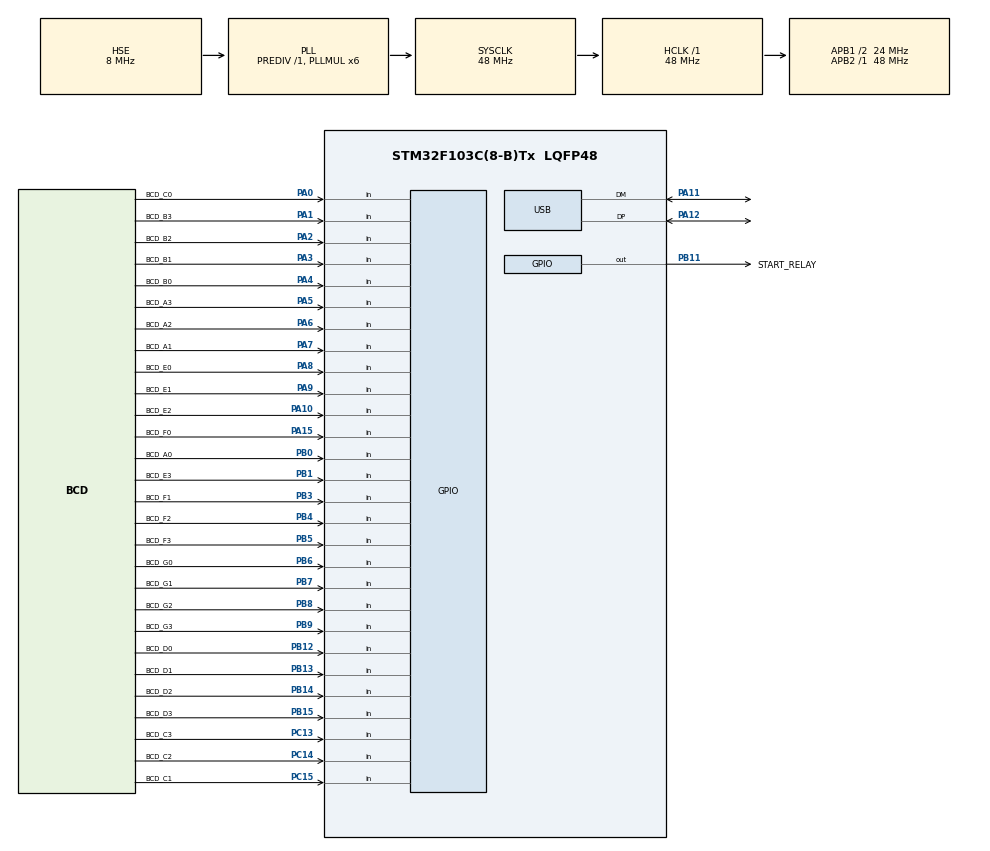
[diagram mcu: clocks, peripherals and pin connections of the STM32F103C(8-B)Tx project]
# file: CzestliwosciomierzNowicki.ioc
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Mcu.Family=STM32F1
Mcu.Name=STM32F103C(8-B)Tx
Mcu.Package=LQFP48
NVIC.PriorityGroup=NVIC_PRIORITYGROUP_4
NVIC.TIM1_UP_IRQn=true\:0\:0\:false\:false\:true\:true\:true
NVIC.USB_LP_CAN1_RX0_IRQn=true\:0\:0\:false\:false\:true\:false\:true
PA0-WKUP.GPIO_Label=BCD_C0
PA0-WKUP.Signal=GPIO_Input
PA1.GPIO_Label=BCD_B3
PA1.Signal=GPIO_Input
PA10.GPIO_Label=BCD_E2
PA10.Signal=GPIO_Input
PA11.Mode=Device
PA11.Signal=USB_DM
PA12.Mode=Device
PA12.Signal=USB_DP
PA13.Mode=Serial_Wire
PA13.Signal=SYS_JTMS-SWDIO
PA14.Mode=Serial_Wire
PA14.Signal=SYS_JTCK-SWCLK
PA15.GPIO_Label=BCD_F0
PA15.Signal=GPIO_Input
PA2.GPIO_Label=BCD_B2
PA2.Signal=GPIO_Input
PA3.GPIO_Label=BCD_B1
PA3.Signal=GPIO_Input
PA4.GPIO_Label=BCD_B0
PA4.Signal=GPIO_Input
PA5.GPIO_Label=BCD_A3
PA5.Signal=GPIO_Input
PA6.GPIO_Label=BCD_A2
PA6.Signal=GPIO_Input
PA7.GPIO_Label=BCD_A1
PA7.Signal=GPIO_Input
PA8.GPIO_Label=BCD_E0
PA8.Signal=GPIO_Input
PA9.GPIO_Label=BCD_E1
PA9.Signal=GPIO_Input
PB0.GPIO_Label=BCD_A0
PB0.Signal=GPIO_Input
PB1.GPIO_Label=BCD_E3
PB1.Signal=GPIO_Input
PB11.GPIO_Label=START_RELAY
PB11.Signal=GPIO_Output
PB12.GPIO_Label=BCD_D0
PB12.Signal=GPIO_Input
PB13.GPIO_Label=BCD_D1
PB13.Signal=GPIO_Input
PB14.GPIO_Label=BCD_D2
PB14.Signal=GPIO_Input
PB15.GPIO_Label=BCD_D3
PB15.Signal=GPIO_Input
PB3.GPIO_Label=BCD_F1
PB3.Signal=GPIO_Input
PB4.GPIO_Label=BCD_F2
PB4.Signal=GPIO_Input
PB5.GPIO_Label=BCD_F3
PB5.Signal=GPIO_Input
PB6.GPIO_Label=BCD_G0
PB6.Signal=GPIO_Input
PB7.GPIO_Label=BCD_G1
PB7.Signal=GPIO_Input
PB8.GPIO_Label=BCD_G2
PB8.Signal=GPIO_Input
PB9.GPIO_Label=BCD_G3
PB9.Signal=GPIO_Input
PC13-TAMPER-RTC.GPIO_Label=BCD_C3
PC13-TAMPER-RTC.Signal=GPIO_Input
PC14-OSC32_IN.GPIO_Label=BCD_C2
PC14-OSC32_IN.Signal=GPIO_Input
PC15-OSC32_OUT.GPIO_Label=BCD_C1
PC15-OSC32_OUT.Signal=GPIO_Input
PD0-OSC_IN.Mode=HSE-External-Oscillator
PD0-OSC_IN.Signal=RCC_OSC_IN
PD1-OSC_OUT.Mode=HSE-External-Oscillator
PD1-OSC_OUT.Signal=RCC_OSC_OUT
ProjectManager.HeapSize=0x200
ProjectManager.StackSize=0x400
ProjectManager.TargetToolchain=STM32CubeIDE
RCC.AHBFreq_Value=48000000
RCC.APB1CLKDivider=RCC_HCLK_DIV2
RCC.APB1Freq_Value=24000000
RCC.APB1TimFreq_Value=48000000
RCC.APB2Freq_Value=48000000
RCC.APB2TimFreq_Value=48000000
RCC.HCLKFreq_Value=48000000
RCC.PLLMUL=RCC_PLL_MUL6
RCC.PLLSourceVirtual=RCC_PLLSOURCE_HSE
RCC.SYSCLKFreq_VALUE=48000000
RCC.SYSCLKSource=RCC_SYSCLKSOURCE_PLLCLK
RCC.USBFreq_Value=48000000
TIM1.AutoReloadPreload=TIM_AUTORELOAD_PRELOAD_ENABLE
TIM1.Period=9
TIM1.Prescaler=47999
USB_DEVICE.CLASS_NAME_FS=CDC
USB_DEVICE.VirtualMode=Cdc
USB_DEVICE.VirtualModeFS=Cdc_FS
VP_TIM1_VS_ClockSourceINT.Mode=Internal
VP_USB_DEVICE_VS_USB_DEVICE_CDC_FS.Mode=CDC_FS
board=custom

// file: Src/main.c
/* USER CODE BEGIN Header */
/**
  ******************************************************************************
  * @file           : main.c
  * @brief          : Main program body
  ******************************************************************************
  * @attention
  *
  * <h2><center>&copy; Copyright (c) 2019 STMicroelectronics.
  * All rights reserved.</center></h2>
  *
  * This software component is licensed by ST under BSD 3-Clause license,
  * the "License"; You may not use this file except in compliance with the
  * License. You may obtain a copy of the License at:
  *                        opensource.org/licenses/BSD-3-Clause
  *
  ******************************************************************************
  */
/* USER CODE END Header */

#include "main.h"
#include "usb_device.h"

TIM_HandleTypeDef htim1;

void SystemClock_Config(void);
static void MX_GPIO_Init(void);
static void MX_TIM1_Init(void);

int main(void)
{

  /* MCU Configuration--------------------------------------------------------*/

  /* Reset of all peripherals, Initializes the Flash interface and the Systick. */
  HAL_Init();

  /* Configure the system clock */
  SystemClock_Config();

  /* Initialize all configured peripherals */
  MX_GPIO_Init();
  MX_USB_DEVICE_Init();
  MX_TIM1_Init();
  /* USER CODE BEGIN 2 */
  ch3_32_Intit(&htim1);
  /* USER CODE END 2 */

  /* Infinite loop */
  /* USER CODE BEGIN WHILE */
  while (1)
  {
	  //temporary -> timer 2 (pulse mode)
	  if(clear == 1){
		HAL_GPIO_WritePin(START_RELAY_GPIO_Port, START_RELAY_Pin, GPIO_PIN_SET);
		HAL_Delay(ch3_32_pulse_time);
		HAL_GPIO_WritePin(START_RELAY_GPIO_Port, START_RELAY_Pin, GPIO_PIN_RESET);
		clear = 0;
	  }
    /* USER CODE END WHILE */

  }
}

void SystemClock_Config(void)
{
  RCC_OscInitTypeDef RCC_OscInitStruct = {0};
  RCC_ClkInitTypeDef RCC_ClkInitStruct = {0};
  RCC_PeriphCLKInitTypeDef PeriphClkInit = {0};

  /** Initializes the CPU, AHB and APB busses clocks
  */
  RCC_OscInitStruct.OscillatorType = RCC_OSCILLATORTYPE_HSE;
  RCC_OscInitStruct.HSEState = RCC_HSE_ON;
  RCC_OscInitStruct.HSEPredivValue = RCC_HSE_PREDIV_DIV1;
  RCC_OscInitStruct.HSIState = RCC_HSI_ON;
  RCC_OscInitStruct.PLL.PLLState = RCC_PLL_ON;
  RCC_OscInitStruct.PLL.PLLSource = RCC_PLLSOURCE_HSE;
  RCC_OscInitStruct.PLL.PLLMUL = RCC_PLL_MUL6;
  if (HAL_RCC_OscConfig(&RCC_OscInitStruct) != HAL_OK)
  {
    Error_Handler();
  }
  /** Initializes the CPU, AHB and APB busses clocks
  */
  RCC_ClkInitStruct.ClockType = RCC_CLOCKTYPE_HCLK|RCC_CLOCKTYPE_SYSCLK
                              |RCC_CLOCKTYPE_PCLK1|RCC_CLOCKTYPE_PCLK2;
  RCC_ClkInitStruct.SYSCLKSource = RCC_SYSCLKSOURCE_PLLCLK;
  RCC_ClkInitStruct.AHBCLKDivider = RCC_SYSCLK_DIV1;
  RCC_ClkInitStruct.APB1CLKDivider = RCC_HCLK_DIV2;
  RCC_ClkInitStruct.APB2CLKDivider = RCC_HCLK_DIV1;

  if (HAL_RCC_ClockConfig(&RCC_ClkInitStruct, FLASH_LATENCY_1) != HAL_OK)
  {
    Error_Handler();
  }
  PeriphClkInit.PeriphClockSelection = RCC_PERIPHCLK_USB;
  PeriphClkInit.UsbClockSelection = RCC_USBCLKSOURCE_PLL;
  if (HAL_RCCEx_PeriphCLKConfig(&PeriphClkInit) != HAL_OK)
  {
    Error_Handler();
  }
}

static void MX_TIM1_Init(void)
{

  TIM_ClockConfigTypeDef sClockSourceConfig = {0};
  TIM_MasterConfigTypeDef sMasterConfig = {0};

  htim1.Instance = TIM1;
  htim1.Init.Prescaler = 47999;
  htim1.Init.CounterMode = TIM_COUNTERMODE_UP;
  htim1.Init.Period = 9;
  htim1.Init.ClockDivision = TIM_CLOCKDIVISION_DIV1;
  htim1.Init.RepetitionCounter = 0;
  htim1.Init.AutoReloadPreload = TIM_AUTORELOAD_PRELOAD_ENABLE;
  if (HAL_TIM_Base_Init(&htim1) != HAL_OK)
  {
    Error_Handler();
  }
  sClockSourceConfig.ClockSource = TIM_CLOCKSOURCE_INTERNAL;
  if (HAL_TIM_ConfigClockSource(&htim1, &sClockSourceConfig) != HAL_OK)
  {
    Error_Handler();
  }
  sMasterConfig.MasterOutputTrigger = TIM_TRGO_RESET;
  sMasterConfig.MasterSlaveMode = TIM_MASTERSLAVEMODE_DISABLE;
  if (HAL_TIMEx_MasterConfigSynchronization(&htim1, &sMasterConfig) != HAL_OK)
  {
    Error_Handler();
  }

}

static void MX_GPIO_Init(void)
{
  GPIO_InitTypeDef GPIO_InitStruct = {0};

  /* GPIO Ports Clock Enable */
  __HAL_RCC_GPIOC_CLK_ENABLE();
  __HAL_RCC_GPIOD_CLK_ENABLE();
  __HAL_RCC_GPIOA_CLK_ENABLE();
  __HAL_RCC_GPIOB_CLK_ENABLE();

  /*Configure GPIO pin Output Level */
  HAL_GPIO_WritePin(START_RELAY_GPIO_Port, START_RELAY_Pin, GPIO_PIN_RESET);

  /*Configure GPIO pins : BCD_C3_Pin BCD_C2_Pin BCD_C1_Pin */
  GPIO_InitStruct.Pin = BCD_C3_Pin|BCD_C2_Pin|BCD_C1_Pin;
  GPIO_InitStruct.Mode = GPIO_MODE_INPUT;
  GPIO_InitStruct.Pull = GPIO_NOPULL;
  HAL_GPIO_Init(GPIOC, &GPIO_InitStruct);

  /*Configure GPIO pins : BCD_C0_Pin BCD_B3_Pin BCD_B2_Pin BCD_B1_Pin
                           BCD_B0_Pin BCD_A3_Pin BCD_A2_Pin BCD_A1_Pin
                           BCD_E0_Pin BCD_E1_Pin BCD_E2_Pin BCD_F0_Pin */
  GPIO_InitStruct.Pin = BCD_C0_Pin|BCD_B3_Pin|BCD_B2_Pin|BCD_B1_Pin
                          |BCD_B0_Pin|BCD_A3_Pin|BCD_A2_Pin|BCD_A1_Pin
                          |BCD_E0_Pin|BCD_E1_Pin|BCD_E2_Pin|BCD_F0_Pin;
  GPIO_InitStruct.Mode = GPIO_MODE_INPUT;
  GPIO_InitStruct.Pull = GPIO_NOPULL;
  HAL_GPIO_Init(GPIOA, &GPIO_InitStruct);

  /*Configure GPIO pins : BCD_A0_Pin BCD_E3_Pin BCD_D0_Pin BCD_D1_Pin
                           BCD_D2_Pin BCD_D3_Pin BCD_F1_Pin BCD_F2_Pin
                           BCD_F3_Pin BCD_G0_Pin BCD_G1_Pin BCD_G2_Pin
                           BCD_G3_Pin */
  GPIO_InitStruct.Pin = BCD_A0_Pin|BCD_E3_Pin|BCD_D0_Pin|BCD_D1_Pin
                          |BCD_D2_Pin|BCD_D3_Pin|BCD_F1_Pin|BCD_F2_Pin
                          |BCD_F3_Pin|BCD_G0_Pin|BCD_G1_Pin|BCD_G2_Pin
                          |BCD_G3_Pin;
  GPIO_InitStruct.Mode = GPIO_MODE_INPUT;
  GPIO_InitStruct.Pull = GPIO_NOPULL;
  HAL_GPIO_Init(GPIOB, &GPIO_InitStruct);

  /*Configure GPIO pin : START_RELAY_Pin */
  GPIO_InitStruct.Pin = START_RELAY_Pin;
  GPIO_InitStruct.Mode = GPIO_MODE_OUTPUT_PP;
  GPIO_InitStruct.Pull = GPIO_NOPULL;
  GPIO_InitStruct.Speed = GPIO_SPEED_FREQ_LOW;
  HAL_GPIO_Init(START_RELAY_GPIO_Port, &GPIO_InitStruct);

}

void Error_Handler(void)
{
}

/************************ (C) COPYRIGHT STMicroelectronics *****END OF FILE****/
